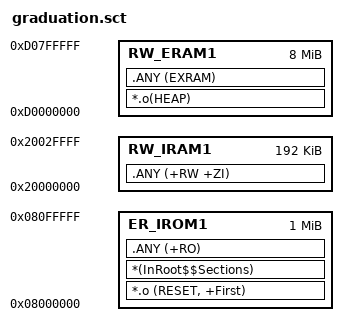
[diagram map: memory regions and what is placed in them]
;/*************************************************************************
;	> File Name: graduation.sct
;	> Author: lvsenlv
;	> Mail: lvsen46000@163.com
;	> Created Time: 2017年04月02日 星期日 21时09分59秒
; ************************************************************************/

LR_IROM1 0x08000000 0x00100000
{
    ; load region size_region
    ER_IROM1 0x08000000 0x00100000
    {
        ; load address
        *.o (RESET, +First)
        *(InRoot$$Sections)
        .ANY (+RO)
    }

    RW_IRAM1 0x20000000 0x00030000
    {
        ; RW data
        .ANY (+RW +ZI)
    }
  
    RW_ERAM1 0xD0000000 0x00800000
    {
        ; 外部SDRAM
        *.o(HEAP)           ;选择堆区
        .ANY (EXRAM)        ;选择EXRAM节区
    }
}

